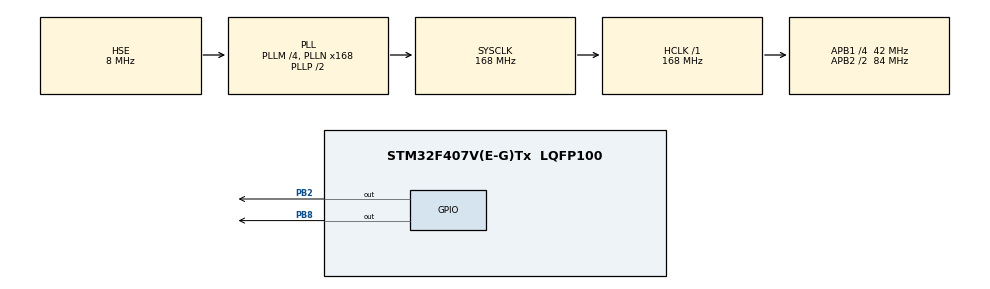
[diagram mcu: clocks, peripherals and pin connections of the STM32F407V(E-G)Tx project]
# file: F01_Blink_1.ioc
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FREERTOS.Tasks01=PB2,24,128,StartPB2,Default,NULL,Dynamic,NULL,NULL;PB8,8,128,StartPB8,Default,NULL,Dynamic,NULL,NULL
Mcu.Family=STM32F4
Mcu.Name=STM32F407V(E-G)Tx
Mcu.Package=LQFP100
NVIC.PriorityGroup=NVIC_PRIORITYGROUP_4
NVIC.TIM8_TRG_COM_TIM14_IRQn=true\:15\:0\:false\:false\:true\:false\:false\:true\:true
NVIC.TimeBase=TIM8_TRG_COM_TIM14_IRQn
NVIC.TimeBaseIP=TIM14
PA13.Mode=Serial_Wire
PA13.Signal=SYS_JTMS-SWDIO
PA14.Mode=Serial_Wire
PA14.Signal=SYS_JTCK-SWCLK
PB2.Signal=GPIO_Output
PB8.Signal=GPIO_Output
PH0-OSC_IN.Mode=HSE-External-Oscillator
PH0-OSC_IN.Signal=RCC_OSC_IN
PH1-OSC_OUT.Mode=HSE-External-Oscillator
PH1-OSC_OUT.Signal=RCC_OSC_OUT
ProjectManager.HeapSize=0x200
ProjectManager.StackSize=0x400
ProjectManager.TargetToolchain=CMake
RCC.48MHZClocksFreq_Value=84000000
RCC.AHBFreq_Value=168000000
RCC.APB1CLKDivider=RCC_HCLK_DIV4
RCC.APB1Freq_Value=42000000
RCC.APB1TimFreq_Value=84000000
RCC.APB2CLKDivider=RCC_HCLK_DIV2
RCC.APB2Freq_Value=84000000
RCC.APB2TimFreq_Value=168000000
RCC.CortexFreq_Value=168000000
RCC.HCLKFreq_Value=168000000
RCC.HSE_VALUE=8000000
RCC.HSI_VALUE=16000000
RCC.LSE_VALUE=32768
RCC.PLLM=4
RCC.PLLN=168
RCC.PLLSourceVirtual=RCC_PLLSOURCE_HSE
RCC.SYSCLKFreq_VALUE=168000000
RCC.SYSCLKSource=RCC_SYSCLKSOURCE_PLLCLK
RCC.VCOOutputFreq_Value=336000000
VP_FREERTOS_VS_CMSIS_V2.Mode=CMSIS_V2
VP_SYS_VS_tim14.Mode=TIM14
board=custom

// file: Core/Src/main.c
/* USER CODE BEGIN Header */
/**
  ******************************************************************************
  * @file           : main.c
  * @brief          : Main program body
  ******************************************************************************
  * @attention
  *
  * Copyright (c) 2026 STMicroelectronics.
  * All rights reserved.
  *
  * This software is licensed under terms that can be found in the LICENSE file
  * in the root directory of this software component.
  * If no LICENSE file comes with this software, it is provided AS-IS.
  *
  ******************************************************************************
  */
/* USER CODE END Header */
#include "main.h"
#include "cmsis_os.h"

/* Definitions for PB2 */
osThreadId_t PB2Handle;
const osThreadAttr_t PB2_attributes = {
  .name = "PB2",
  .stack_size = 128 * 4,
  .priority = (osPriority_t) osPriorityNormal,
};
/* Definitions for PB8 */
osThreadId_t PB8Handle;
const osThreadAttr_t PB8_attributes = {
  .name = "PB8",
  .stack_size = 128 * 4,
  .priority = (osPriority_t) osPriorityLow,
};

void SystemClock_Config(void);
static void MX_GPIO_Init(void);
void StartPB2(void *argument);
void StartPB8(void *argument);

int main(void)
{

  /* MCU Configuration--------------------------------------------------------*/

  /* Reset of all peripherals, Initializes the Flash interface and the Systick. */
  HAL_Init();

  /* Configure the system clock */
  SystemClock_Config();

  /* Initialize all configured peripherals */
  MX_GPIO_Init();

  /* Init scheduler */
  osKernelInitialize();

  /* Create the thread(s) */
  /* creation of PB2 */
  PB2Handle = osThreadNew(StartPB2, NULL, &PB2_attributes);

  /* creation of PB8 */
  PB8Handle = osThreadNew(StartPB8, NULL, &PB8_attributes);

  /* Start scheduler */
  osKernelStart();

  /* We should never get here as control is now taken by the scheduler */

  /* Infinite loop */
  while (1)
  {

  }
}

void SystemClock_Config(void)
{
  RCC_OscInitTypeDef RCC_OscInitStruct = {0};
  RCC_ClkInitTypeDef RCC_ClkInitStruct = {0};

  /** Configure the main internal regulator output voltage
  */
  __HAL_RCC_PWR_CLK_ENABLE();
  __HAL_PWR_VOLTAGESCALING_CONFIG(PWR_REGULATOR_VOLTAGE_SCALE1);

  /** Initializes the RCC Oscillators according to the specified parameters
  * in the RCC_OscInitTypeDef structure.
  */
  RCC_OscInitStruct.OscillatorType = RCC_OSCILLATORTYPE_HSE;
  RCC_OscInitStruct.HSEState = RCC_HSE_ON;
  RCC_OscInitStruct.PLL.PLLState = RCC_PLL_ON;
  RCC_OscInitStruct.PLL.PLLSource = RCC_PLLSOURCE_HSE;
  RCC_OscInitStruct.PLL.PLLM = 4;
  RCC_OscInitStruct.PLL.PLLN = 168;
  RCC_OscInitStruct.PLL.PLLP = RCC_PLLP_DIV2;
  RCC_OscInitStruct.PLL.PLLQ = 4;
  if (HAL_RCC_OscConfig(&RCC_OscInitStruct) != HAL_OK)
  {
    Error_Handler();
  }

  /** Initializes the CPU, AHB and APB buses clocks
  */
  RCC_ClkInitStruct.ClockType = RCC_CLOCKTYPE_HCLK|RCC_CLOCKTYPE_SYSCLK
                              |RCC_CLOCKTYPE_PCLK1|RCC_CLOCKTYPE_PCLK2;
  RCC_ClkInitStruct.SYSCLKSource = RCC_SYSCLKSOURCE_PLLCLK;
  RCC_ClkInitStruct.AHBCLKDivider = RCC_SYSCLK_DIV1;
  RCC_ClkInitStruct.APB1CLKDivider = RCC_HCLK_DIV4;
  RCC_ClkInitStruct.APB2CLKDivider = RCC_HCLK_DIV2;

  if (HAL_RCC_ClockConfig(&RCC_ClkInitStruct, FLASH_LATENCY_5) != HAL_OK)
  {
    Error_Handler();
  }
}

static void MX_GPIO_Init(void)
{
  GPIO_InitTypeDef GPIO_InitStruct = {0};

  /* GPIO Ports Clock Enable */
  __HAL_RCC_GPIOH_CLK_ENABLE();
  __HAL_RCC_GPIOB_CLK_ENABLE();
  __HAL_RCC_GPIOA_CLK_ENABLE();

  /*Configure GPIO pin Output Level */
  HAL_GPIO_WritePin(GPIOB, GPIO_PIN_2|GPIO_PIN_8, GPIO_PIN_RESET);

  /*Configure GPIO pins : PB2 PB8 */
  GPIO_InitStruct.Pin = GPIO_PIN_2|GPIO_PIN_8;
  GPIO_InitStruct.Mode = GPIO_MODE_OUTPUT_PP;
  GPIO_InitStruct.Pull = GPIO_NOPULL;
  GPIO_InitStruct.Speed = GPIO_SPEED_FREQ_LOW;
  HAL_GPIO_Init(GPIOB, &GPIO_InitStruct);

}

void StartPB2(void *argument)
{
  /* USER CODE BEGIN 5 */
  /* Infinite loop */
  for(;;)
  {
    HAL_GPIO_TogglePin(GPIOB, GPIO_PIN_2);
    osDelay(1000);
  }
  /* USER CODE END 5 */
}

void StartPB8(void *argument)
{
  /* USER CODE BEGIN StartPB8 */
  /* Infinite loop */
  for(;;)
  {
    HAL_GPIO_TogglePin(GPIOB, GPIO_PIN_8);
    osDelay(800);
  }
  /* USER CODE END StartPB8 */
}

void HAL_TIM_PeriodElapsedCallback(TIM_HandleTypeDef *htim)
{
  if (htim->Instance == TIM14)
  {
    HAL_IncTick();
  }
}

void Error_Handler(void)
{
  __disable_irq();
  while (1)
  {
  }
}
